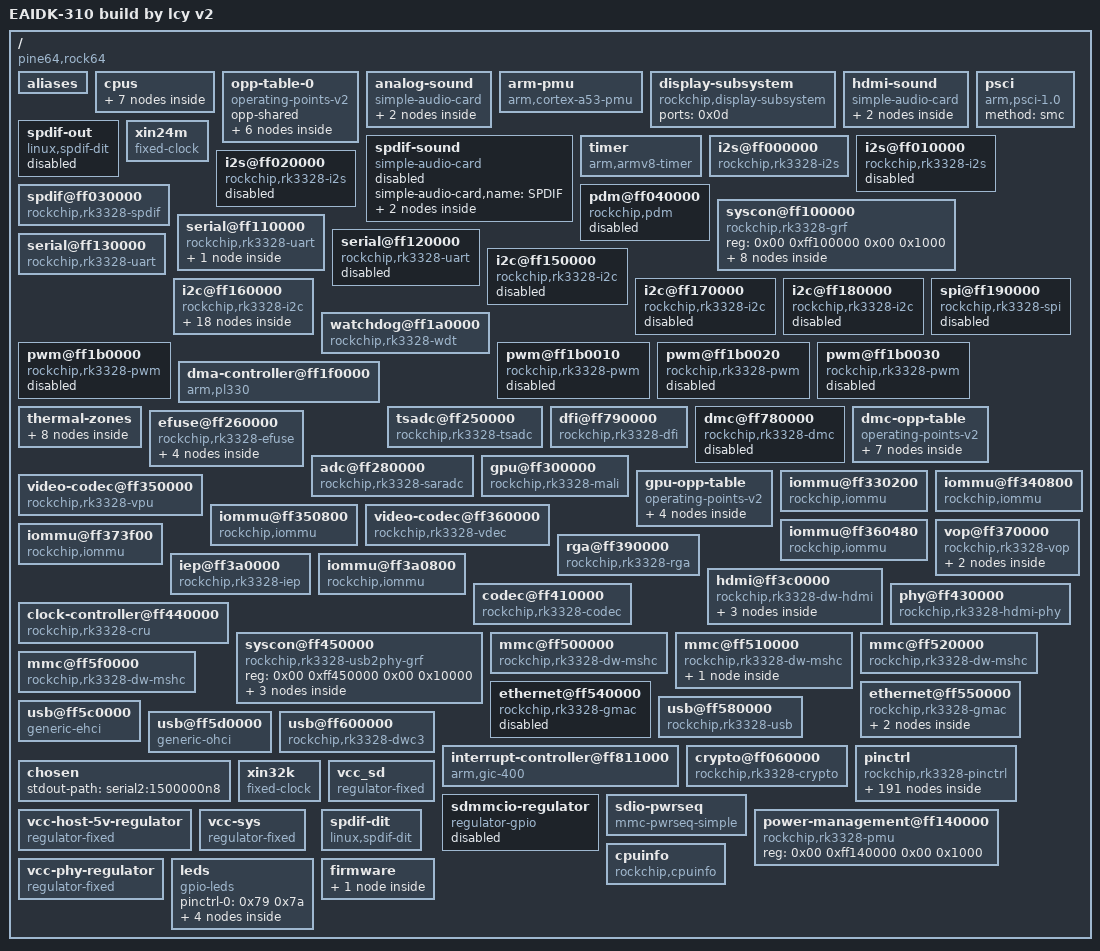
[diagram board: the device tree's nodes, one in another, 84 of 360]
/dts-v1/;

/ {
	compatible = "pine64,rock64\0rockchip,rk3328";
	interrupt-parent = <0x01>;
	#address-cells = <0x02>;
	#size-cells = <0x02>;
	model = "EAIDK-310 build by lcy v2";

	aliases {
		gpio0 = "/pinctrl/gpio@ff210000";
		gpio1 = "/pinctrl/gpio@ff220000";
		gpio2 = "/pinctrl/gpio@ff230000";
		gpio3 = "/pinctrl/gpio@ff240000";
		serial0 = "/serial@ff110000";
		serial1 = "/serial@ff120000";
		serial2 = "/serial@ff130000";
		i2c0 = "/i2c@ff150000";
		i2c1 = "/i2c@ff160000";
		i2c2 = "/i2c@ff170000";
		i2c3 = "/i2c@ff180000";
		mmc0 = "/mmc@ff500000";
		mmc1 = "/mmc@ff510000";
		mmc2 = "/mmc@ff520000";
		mmc3 = "/mmc@ff5f0000";
	};

	cpus {
		#address-cells = <0x02>;
		#size-cells = <0x00>;

		cpu@0 {
			device_type = "cpu";
			compatible = "arm,cortex-a53";
			reg = <0x00 0x00>;
			clocks = <0x02 0x06>;
			#cooling-cells = <0x02>;
			cpu-idle-states = <0x03>;
			dynamic-power-coefficient = <0x78>;
			enable-method = "psci";
			next-level-cache = <0x04>;
			operating-points-v2 = <0x05>;
			cpu-supply = <0x06>;
			phandle = <0x09>;
		};

		cpu@1 {
			device_type = "cpu";
			compatible = "arm,cortex-a53";
			reg = <0x00 0x01>;
			clocks = <0x02 0x06>;
			#cooling-cells = <0x02>;
			cpu-idle-states = <0x03>;
			dynamic-power-coefficient = <0x78>;
			enable-method = "psci";
			next-level-cache = <0x04>;
			operating-points-v2 = <0x05>;
			cpu-supply = <0x06>;
			phandle = <0x0a>;
		};

		cpu@2 {
			device_type = "cpu";
			compatible = "arm,cortex-a53";
			reg = <0x00 0x02>;
			clocks = <0x02 0x06>;
			#cooling-cells = <0x02>;
			cpu-idle-states = <0x03>;
			dynamic-power-coefficient = <0x78>;
			enable-method = "psci";
			next-level-cache = <0x04>;
			operating-points-v2 = <0x05>;
			cpu-supply = <0x06>;
			phandle = <0x0b>;
		};

		cpu@3 {
			device_type = "cpu";
			compatible = "arm,cortex-a53";
			reg = <0x00 0x03>;
			clocks = <0x02 0x06>;
			#cooling-cells = <0x02>;
			cpu-idle-states = <0x03>;
			dynamic-power-coefficient = <0x78>;
			enable-method = "psci";
			next-level-cache = <0x04>;
			operating-points-v2 = <0x05>;
			cpu-supply = <0x06>;
			phandle = <0x0c>;
		};

		idle-states {
			entry-method = "psci";

			cpu-sleep {
				compatible = "arm,idle-state";
				local-timer-stop;
				arm,psci-suspend-param = <0x10000>;
				entry-latency-us = <0x78>;
				exit-latency-us = <0xfa>;
				min-residency-us = <0x384>;
				phandle = <0x03>;
			};
		};

		l2-cache0 {
			compatible = "cache";
			cache-level = <0x02>;
			cache-unified;
			phandle = <0x04>;
		};
	};

	opp-table-0 {
		compatible = "operating-points-v2";
		opp-shared;
		phandle = <0x05>;

		opp-408000000 {
			opp-hz = <0x00 0x18519600>;
			opp-microvolt = <0xe7ef0>;
			clock-latency-ns = <0x9c40>;
			opp-suspend;
		};

		opp-600000000 {
			opp-hz = <0x00 0x23c34600>;
			opp-microvolt = <0xe7ef0>;
			clock-latency-ns = <0x9c40>;
		};

		opp-816000000 {
			opp-hz = <0x00 0x30a32c00>;
			opp-microvolt = <0xf4240>;
			clock-latency-ns = <0x9c40>;
		};

		opp-1008000000 {
			opp-hz = <0x00 0x3c14dc00>;
			opp-microvolt = <0x10c8e0>;
			clock-latency-ns = <0x9c40>;
		};

		opp-1200000000 {
			opp-hz = <0x00 0x47868c00>;
			opp-microvolt = <0x12b128>;
			clock-latency-ns = <0x9c40>;
		};

		opp-1296000000 {
			opp-hz = <0x00 0x4d3f6400>;
			opp-microvolt = <0x13d620>;
			clock-latency-ns = <0x9c40>;
		};
	};

	analog-sound {
		compatible = "simple-audio-card";
		simple-audio-card,format = "i2s";
		simple-audio-card,mclk-fs = <0x100>;
		simple-audio-card,name = "Analog";
		status = "okay";

		simple-audio-card,cpu {
			sound-dai = <0x07>;
		};

		simple-audio-card,codec {
			sound-dai = <0x08>;
		};
	};

	arm-pmu {
		compatible = "arm,cortex-a53-pmu";
		interrupts = <0x00 0x64 0x04 0x00 0x65 0x04 0x00 0x66 0x04 0x00 0x67 0x04>;
		interrupt-affinity = <0x09 0x0a 0x0b 0x0c>;
	};

	display-subsystem {
		compatible = "rockchip,display-subsystem";
		ports = <0x0d>;
	};

	hdmi-sound {
		compatible = "simple-audio-card";
		simple-audio-card,format = "i2s";
		simple-audio-card,mclk-fs = <0x80>;
		simple-audio-card,name = "HDMI";
		status = "okay";

		simple-audio-card,cpu {
			sound-dai = <0x0e>;
		};

		simple-audio-card,codec {
			sound-dai = <0x0f>;
		};
	};

	psci {
		compatible = "arm,psci-1.0\0arm,psci-0.2";
		method = "smc";
	};

	spdif-out {
		compatible = "linux,spdif-dit";
		#sound-dai-cells = <0x00>;
		status = "disabled";
	};

	spdif-sound {
		compatible = "simple-audio-card";
		simple-audio-card,name = "SPDIF";
		status = "disabled";

		simple-audio-card,cpu {
			sound-dai = <0x10>;
		};

		simple-audio-card,codec {
			sound-dai = <0x11>;
		};
	};

	timer {
		compatible = "arm,armv8-timer";
		interrupts = <0x01 0x0d 0xf08 0x01 0x0e 0xf08 0x01 0x0b 0xf08 0x01 0x0a 0xf08>;
	};

	xin24m {
		compatible = "fixed-clock";
		#clock-cells = <0x00>;
		clock-frequency = <0x16e3600>;
		clock-output-names = "xin24m";
		phandle = <0x51>;
	};

	i2s@ff000000 {
		compatible = "rockchip,rk3328-i2s\0rockchip,rk3066-i2s";
		reg = <0x00 0xff000000 0x00 0x1000>;
		interrupts = <0x00 0x1a 0x04>;
		clocks = <0x02 0x29 0x02 0x137>;
		clock-names = "i2s_clk\0i2s_hclk";
		dmas = <0x12 0x0b 0x12 0x0c>;
		dma-names = "tx\0rx";
		#sound-dai-cells = <0x00>;
		status = "okay";
		phandle = <0x0e>;
	};

	i2s@ff010000 {
		compatible = "rockchip,rk3328-i2s\0rockchip,rk3066-i2s";
		reg = <0x00 0xff010000 0x00 0x1000>;
		interrupts = <0x00 0x1b 0x04>;
		clocks = <0x02 0x2a 0x02 0x138>;
		clock-names = "i2s_clk\0i2s_hclk";
		dmas = <0x12 0x0e 0x12 0x0f>;
		dma-names = "tx\0rx";
		#sound-dai-cells = <0x00>;
		status = "disabled";
		phandle = <0x07>;
	};

	i2s@ff020000 {
		compatible = "rockchip,rk3328-i2s\0rockchip,rk3066-i2s";
		reg = <0x00 0xff020000 0x00 0x1000>;
		interrupts = <0x00 0x1c 0x04>;
		clocks = <0x02 0x2b 0x02 0x139>;
		clock-names = "i2s_clk\0i2s_hclk";
		dmas = <0x12 0x00 0x12 0x01>;
		dma-names = "tx\0rx";
		#sound-dai-cells = <0x00>;
		status = "disabled";
	};

	spdif@ff030000 {
		compatible = "rockchip,rk3328-spdif";
		reg = <0x00 0xff030000 0x00 0x1000>;
		interrupts = <0x00 0x1d 0x04>;
		clocks = <0x02 0x2e 0x02 0x13a>;
		clock-names = "mclk\0hclk";
		dmas = <0x12 0x0a>;
		dma-names = "tx";
		pinctrl-names = "default";
		pinctrl-0 = <0x13>;
		#sound-dai-cells = <0x00>;
		status = "okay";
		phandle = <0x10>;
	};

	pdm@ff040000 {
		compatible = "rockchip,pdm";
		reg = <0x00 0xff040000 0x00 0x1000>;
		clocks = <0x02 0x3d 0x02 0x152>;
		clock-names = "pdm_clk\0pdm_hclk";
		dmas = <0x12 0x10>;
		dma-names = "rx";
		pinctrl-names = "default\0sleep";
		pinctrl-0 = <0x14 0x15 0x16 0x17 0x18>;
		pinctrl-1 = <0x19 0x1a 0x1b 0x1c 0x1d>;
		status = "disabled";
	};

	syscon@ff100000 {
		compatible = "rockchip,rk3328-grf\0syscon\0simple-mfd";
		reg = <0x00 0xff100000 0x00 0x1000>;
		phandle = <0x40>;

		io-domains {
			compatible = "rockchip,rk3328-io-voltage-domain";
			status = "okay";
			vccio1-supply = <0x1e>;
			vccio2-supply = <0x1f>;
			vccio3-supply = <0x20>;
			vccio4-supply = <0x20>;
			vccio5-supply = <0x1e>;
			vccio6-supply = <0x1e>;
			pmuio-supply = <0x1e>;
		};

		gpio {
			compatible = "rockchip,rk3328-grf-gpio";
			gpio-controller;
			#gpio-cells = <0x02>;
			phandle = <0x50>;
		};

		power-controller {
			compatible = "rockchip,rk3328-power-controller";
			#power-domain-cells = <0x01>;
			#address-cells = <0x01>;
			#size-cells = <0x00>;
			phandle = <0x43>;

			power-domain@1 {
				reg = <0x01>;
				clocks = <0x02 0x87>;
			};

			power-domain@6 {
				reg = <0x06>;
				#power-domain-cells = <0x00>;
			};

			power-domain@5 {
				reg = <0x05>;
				clocks = <0x02 0x8b 0x02 0x142 0x02 0x41 0x02 0x42>;
				#power-domain-cells = <0x00>;
			};

			power-domain@8 {
				reg = <0x08>;
				clocks = <0x02 0x8f 0x02 0x146>;
				#power-domain-cells = <0x00>;
			};
		};

		reboot-mode {
			compatible = "syscon-reboot-mode";
			offset = <0x5c8>;
			mode-normal = <0x5242c300>;
			mode-recovery = <0x5242c303>;
			mode-bootloader = <0x5242c309>;
			mode-loader = <0x5242c301>;
		};
	};

	serial@ff110000 {
		compatible = "rockchip,rk3328-uart\0snps,dw-apb-uart";
		reg = <0x00 0xff110000 0x00 0x100>;
		interrupts = <0x00 0x37 0x04>;
		clocks = <0x02 0x26 0x02 0xd2>;
		clock-names = "baudclk\0apb_pclk";
		dmas = <0x12 0x02 0x12 0x03>;
		dma-names = "tx\0rx";
		pinctrl-names = "default";
		pinctrl-0 = <0x21 0x22 0x23>;
		reg-io-width = <0x04>;
		reg-shift = <0x02>;
		status = "okay";

		bluetooth {
			compatible = "brcm,bcm4345c5\0brcm,bcm4334b0-bt\0brcm,bcm4330-bt";
			clocks = <0x24 0x01>;
			clock-names = "lpo";
			host-wakeup-gpios = <0x25 0x1a 0x00>;
			shutdown-gpios = <0x25 0x15 0x00>;
			pinctrl-names = "default";
			max-speed = "\0=\t";
			pinctrl-0 = <0x26 0x27>;
			vbat-supply = <0x1e>;
			vddio-supply = <0x20>;
		};
	};

	serial@ff120000 {
		compatible = "rockchip,rk3328-uart\0snps,dw-apb-uart";
		reg = <0x00 0xff120000 0x00 0x100>;
		interrupts = <0x00 0x38 0x04>;
		clocks = <0x02 0x27 0x02 0xd3>;
		clock-names = "baudclk\0apb_pclk";
		dmas = <0x12 0x04 0x12 0x05>;
		dma-names = "tx\0rx";
		pinctrl-names = "default";
		pinctrl-0 = <0x28 0x29 0x2a>;
		reg-io-width = <0x04>;
		reg-shift = <0x02>;
		status = "disabled";
	};

	serial@ff130000 {
		compatible = "rockchip,rk3328-uart\0snps,dw-apb-uart";
		reg = <0x00 0xff130000 0x00 0x100>;
		interrupts = <0x00 0x39 0x04>;
		clocks = <0x02 0x28 0x02 0xd4>;
		clock-names = "baudclk\0apb_pclk";
		dmas = <0x12 0x06 0x12 0x07>;
		dma-names = "tx\0rx";
		pinctrl-names = "default";
		pinctrl-0 = <0x2b>;
		reg-io-width = <0x04>;
		reg-shift = <0x02>;
		status = "okay";
	};

	i2c@ff150000 {
		compatible = "rockchip,rk3328-i2c\0rockchip,rk3399-i2c";
		reg = <0x00 0xff150000 0x00 0x1000>;
		interrupts = <0x00 0x24 0x04>;
		#address-cells = <0x01>;
		#size-cells = <0x00>;
		clocks = <0x02 0x37 0x02 0xcd>;
		clock-names = "i2c\0pclk";
		pinctrl-names = "default";
		pinctrl-0 = <0x2c>;
		status = "disabled";
	};

	i2c@ff160000 {
		compatible = "rockchip,rk3328-i2c\0rockchip,rk3399-i2c";
		reg = <0x00 0xff160000 0x00 0x1000>;
		interrupts = <0x00 0x25 0x04>;
		#address-cells = <0x01>;
		#size-cells = <0x00>;
		clocks = <0x02 0x38 0x02 0xce>;
		clock-names = "i2c\0pclk";
		pinctrl-names = "default";
		pinctrl-0 = <0x2d>;
		status = "okay";

		pmic@18 {
			compatible = "rockchip,rk805";
			reg = <0x18>;
			interrupt-parent = <0x2e>;
			interrupts = <0x18 0x08>;
			#clock-cells = <0x01>;
			#gpio-cells = <0x02>;
			clock-output-names = "xin32k\0rk805-clkout2";
			gpio-controller;
			pinctrl-names = "default";
			pinctrl-0 = <0x2f>;
			rockchip,system-power-controller;
			wakeup-source;
			status = "okay";
			vcc1-supply = <0x30>;
			vcc2-supply = <0x30>;
			vcc3-supply = <0x30>;
			vcc4-supply = <0x30>;
			vcc5-supply = <0x1e>;
			vcc6-supply = <0x30>;
			phandle = <0x24>;

			rtc {
				status = "okay";
			};

			gpio {
				status = "okay";
			};

			regulators {
				compatible = "rk805-regulator";
				status = "okay";

				DCDC_REG1 {
					regulator-name = "vdd_logic";
					regulator-min-microvolt = <0xadf34>;
					regulator-max-microvolt = <0x162010>;
					regulator-ramp-delay = <0x30d4>;
					regulator-always-on;
					regulator-boot-on;
					phandle = <0x45>;

					regulator-state-mem {
						regulator-on-in-suspend;
						regulator-suspend-microvolt = <0xf4240>;
					};
				};

				DCDC_REG2 {
					regulator-name = "vdd_arm";
					regulator-min-microvolt = <0xadf34>;
					regulator-max-microvolt = <0x162010>;
					regulator-ramp-delay = <0x30d4>;
					regulator-always-on;
					regulator-boot-on;
					phandle = <0x06>;

					regulator-state-mem {
						regulator-on-in-suspend;
						regulator-suspend-microvolt = <0xe7ef0>;
					};
				};

				DCDC_REG3 {
					regulator-name = "vcc_ddr";
					regulator-always-on;
					regulator-boot-on;

					regulator-state-mem {
						regulator-on-in-suspend;
					};
				};

				DCDC_REG4 {
					regulator-name = "vcc_io";
					regulator-min-microvolt = <0x325aa0>;
					regulator-max-microvolt = <0x325aa0>;
					regulator-always-on;
					regulator-boot-on;
					phandle = <0x1e>;

					regulator-state-mem {
						regulator-on-in-suspend;
						regulator-suspend-microvolt = <0x325aa0>;
					};
				};

				LDO_REG1 {
					regulator-name = "vcc_18";
					regulator-min-microvolt = <0x1b7740>;
					regulator-max-microvolt = <0x1b7740>;
					regulator-always-on;
					regulator-boot-on;
					phandle = <0x20>;

					regulator-state-mem {
						regulator-on-in-suspend;
						regulator-suspend-microvolt = <0x1b7740>;
					};
				};

				LDO_REG2 {
					regulator-name = "vcc18_emmc";
					regulator-min-microvolt = <0x1b7740>;
					regulator-max-microvolt = <0x1b7740>;
					regulator-always-on;
					regulator-boot-on;
					phandle = <0x1f>;

					regulator-state-mem {
						regulator-on-in-suspend;
						regulator-suspend-microvolt = <0x1b7740>;
					};
				};

				LDO_REG3 {
					regulator-name = "vdd_10";
					regulator-min-microvolt = <0xf4240>;
					regulator-max-microvolt = <0xf4240>;
					regulator-always-on;
					regulator-boot-on;

					regulator-state-mem {
						regulator-on-in-suspend;
						regulator-suspend-microvolt = <0xf4240>;
					};
				};
			};
		};
	};

	i2c@ff170000 {
		compatible = "rockchip,rk3328-i2c\0rockchip,rk3399-i2c";
		reg = <0x00 0xff170000 0x00 0x1000>;
		interrupts = <0x00 0x26 0x04>;
		#address-cells = <0x01>;
		#size-cells = <0x00>;
		clocks = <0x02 0x39 0x02 0xcf>;
		clock-names = "i2c\0pclk";
		pinctrl-names = "default";
		pinctrl-0 = <0x31>;
		status = "disabled";
	};

	i2c@ff180000 {
		compatible = "rockchip,rk3328-i2c\0rockchip,rk3399-i2c";
		reg = <0x00 0xff180000 0x00 0x1000>;
		interrupts = <0x00 0x27 0x04>;
		#address-cells = <0x01>;
		#size-cells = <0x00>;
		clocks = <0x02 0x3a 0x02 0xd0>;
		clock-names = "i2c\0pclk";
		pinctrl-names = "default";
		pinctrl-0 = <0x32>;
		status = "disabled";
	};

	spi@ff190000 {
		compatible = "rockchip,rk3328-spi\0rockchip,rk3066-spi";
		reg = <0x00 0xff190000 0x00 0x1000>;
		interrupts = <0x00 0x31 0x04>;
		#address-cells = <0x01>;
		#size-cells = <0x00>;
		clocks = <0x02 0x20 0x02 0xd1>;
		clock-names = "spiclk\0apb_pclk";
		dmas = <0x12 0x08 0x12 0x09>;
		dma-names = "tx\0rx";
		pinctrl-names = "default";
		pinctrl-0 = <0x33 0x34 0x35 0x36>;
		status = "disabled";
	};

	watchdog@ff1a0000 {
		compatible = "rockchip,rk3328-wdt\0snps,dw-wdt";
		reg = <0x00 0xff1a0000 0x00 0x100>;
		interrupts = <0x00 0x28 0x04>;
		clocks = <0x02 0xec>;
	};

	pwm@ff1b0000 {
		compatible = "rockchip,rk3328-pwm";
		reg = <0x00 0xff1b0000 0x00 0x10>;
		clocks = <0x02 0x3c 0x02 0xd6>;
		clock-names = "pwm\0pclk";
		pinctrl-names = "default";
		pinctrl-0 = <0x37>;
		#pwm-cells = <0x03>;
		status = "disabled";
	};

	pwm@ff1b0010 {
		compatible = "rockchip,rk3328-pwm";
		reg = <0x00 0xff1b0010 0x00 0x10>;
		clocks = <0x02 0x3c 0x02 0xd6>;
		clock-names = "pwm\0pclk";
		pinctrl-names = "default";
		pinctrl-0 = <0x38>;
		#pwm-cells = <0x03>;
		status = "disabled";
	};

	pwm@ff1b0020 {
		compatible = "rockchip,rk3328-pwm";
		reg = <0x00 0xff1b0020 0x00 0x10>;
		clocks = <0x02 0x3c 0x02 0xd6>;
		clock-names = "pwm\0pclk";
		pinctrl-names = "default";
		pinctrl-0 = <0x39>;
		#pwm-cells = <0x03>;
		status = "disabled";
	};

	pwm@ff1b0030 {
		compatible = "rockchip,rk3328-pwm";
		reg = <0x00 0xff1b0030 0x00 0x10>;
		interrupts = <0x00 0x32 0x04>;
		clocks = <0x02 0x3c 0x02 0xd6>;
		clock-names = "pwm\0pclk";
		pinctrl-names = "default";
		pinctrl-0 = <0x3a>;
		#pwm-cells = <0x03>;
		status = "disabled";
	};

	dma-controller@ff1f0000 {
		compatible = "arm,pl330\0arm,primecell";
		reg = <0x00 0xff1f0000 0x00 0x4000>;
		interrupts = <0x00 0x00 0x04 0x00 0x01 0x04>;
		arm,pl330-periph-burst;
		clocks = <0x02 0x86>;
		clock-names = "apb_pclk";
		#dma-cells = <0x01>;
		phandle = <0x12>;
	};

	thermal-zones {

		soc-thermal {
			polling-delay-passive = <0x14>;
			polling-delay = <0x3e8>;
			sustainable-power = <0x3e8>;
			thermal-sensors = <0x3b 0x00>;

			trips {

				trip-point0 {
					temperature = <0x11170>;
					hysteresis = <0x7d0>;
					type = "passive";
				};

				trip-point1 {
					temperature = <0x14c08>;
					hysteresis = <0x7d0>;
					type = "passive";
					phandle = <0x3c>;
				};

				soc-crit {
					temperature = <0x17318>;
					hysteresis = <0x7d0>;
					type = "critical";
				};
			};

			cooling-maps {

				map0 {
					trip = <0x3c>;
					cooling-device = <0x09 0xffffffff 0xffffffff 0x0a 0xffffffff 0xffffffff 0x0b 0xffffffff 0xffffffff 0x0c 0xffffffff 0xffffffff>;
					contribution = <0x1000>;
				};

				map1 {
					trip = <0x3c>;
					cooling-device = <0x3d 0xffffffff 0xffffffff>;
					contribution = <0x1000>;
				};
			};
		};
	};

	tsadc@ff250000 {
		compatible = "rockchip,rk3328-tsadc";
		reg = <0x00 0xff250000 0x00 0x100>;
		interrupts = <0x00 0x3a 0x04>;
		assigned-clocks = <0x02 0x24>;
		assigned-clock-rates = <0xc350>;
		clocks = <0x02 0x24 0x02 0xd5>;
		clock-names = "tsadc\0apb_pclk";
		pinctrl-names = "init\0default\0sleep";
		pinctrl-0 = <0x3e>;
		pinctrl-1 = <0x3f>;
		pinctrl-2 = <0x3e>;
		resets = <0x02 0x42>;
		reset-names = "tsadc-apb";
		rockchip,grf = <0x40>;
		rockchip,hw-tshut-temp = <0x186a0>;
		#thermal-sensor-cells = <0x01>;
		status = "okay";
		rockchip,hw-tshut-mode = <0x00>;
		rockchip,hw-tshut-polarity = <0x00>;
		phandle = <0x3b>;
	};

	dfi@ff790000 {
		reg = <0x00 0xff790000 0x00 0x400>;
		compatible = "rockchip,rk3328-dfi";
		rockchip,grf = <0x40>;
		status = "okay";
		phandle = <0x41>;
	};

	dmc@ff780000 {
		reg = <0x00 0xff780000 0x00 0x400>;
		compatible = "rockchip,rk3328-dmc";
		devfreq-events = <0x41>;
		clocks = <0x02 0x40>;
		clock-names = "dmc_clk";
		operating-points-v2 = <0x42>;
		#cooling-cells = <0x02>;
		status = "disabled";
	};

	dmc-opp-table {
		compatible = "operating-points-v2";
		phandle = <0x42>;

		opp-600000000 {
			opp-hz = <0x00 0x23c34600>;
			opp-microvolt = <0xf4240 0xf4240 0x124f80>;
		};

		opp-666000000 {
			opp-hz = <0x00 0x27b25a80>;
			opp-microvolt = <0xfa3e8 0xfa3e8 0x124f80>;
		};

		opp-786000000 {
			opp-hz = <0x00 0x2ed96880>;
			opp-microvolt = <0x100590 0x100590 0x124f80>;
		};

		opp-800000000 {
			opp-hz = <0x00 0x2faf0800>;
			opp-microvolt = <0x100590 0x100590 0x124f80>;
			status = "disabled";
		};

		opp-850000000 {
			opp-hz = <0x00 0x32a9f880>;
			opp-microvolt = <0x100590 0x100590 0x124f80>;
			status = "disabled";
		};

		opp-933000000 {
			opp-hz = <0x00 0x379c7340>;
			opp-microvolt = <0x10c8e0 0x10c8e0 0x124f80>;
			status = "disabled";
		};

		opp-1066000000 {
			opp-hz = <0x00 0x3f89de80>;
			opp-microvolt = <0x118c30 0x118c30 0x124f80>;
			status = "disabled";
		};
	};

	efuse@ff260000 {
		compatible = "rockchip,rk3328-efuse";
		reg = <0x00 0xff260000 0x00 0x50>;
		#address-cells = <0x01>;
		#size-cells = <0x01>;
		clocks = <0x02 0x3e>;
		clock-names = "pclk_efuse";
		rockchip,efuse-size = <0x20>;

		id@7 {
			reg = <0x07 0x10>;
		};

		cpu-leakage@17 {
			reg = <0x17 0x01>;
		};

		logic-leakage@19 {
			reg = <0x19 0x01>;
		};

		cpu-version@1a {
			reg = <0x1a 0x01>;
			bits = <0x03 0x03>;
			phandle = <0x52>;
		};
	};

	adc@ff280000 {
		compatible = "rockchip,rk3328-saradc\0rockchip,rk3399-saradc";
		reg = <0x00 0xff280000 0x00 0x100>;
		interrupts = <0x00 0x50 0x04>;
		#io-channel-cells = <0x01>;
		clocks = <0x02 0x25 0x02 0xea>;
		clock-names = "saradc\0apb_pclk";
		resets = <0x02 0x56>;
		reset-names = "saradc-apb";
		status = "okay";
		vref-supply = <0x20>;
	};

	gpu@ff300000 {
		compatible = "rockchip,rk3328-mali\0arm,mali-450";
		reg = <0x00 0xff300000 0x00 0x30000>;
		interrupts = <0x00 0x5a 0x04 0x00 0x57 0x04 0x00 0x5d 0x04 0x00 0x58 0x04 0x00 0x59 0x04 0x00 0x5b 0x04 0x00 0x5c 0x04>;
		interrupt-names = "gp\0gpmmu\0pp\0pp0\0ppmmu0\0pp1\0ppmmu1";
		clocks = <0x02 0x87 0x02 0x87>;
		clock-names = "bus\0core";
		power-domains = <0x43 0x01>;
		resets = <0x02 0x66>;
		operating-points-v2 = <0x44>;
		#cooling-cells = <0x02>;
		status = "okay";
		mali-supply = <0x45>;
		phandle = <0x3d>;
	};

	gpu-opp-table {
		compatible = "operating-points-v2";
		phandle = <0x44>;

		opp-200000000 {
			opp-hz = <0x00 0xbebc200>;
			opp-microvolt = <0x100590 0xe7ef0 0x124f80>;
		};

		opp-300000000 {
			opp-hz = <0x00 0x11e1a300>;
			opp-microvolt = <0x100590 0xe7ef0 0x124f80>;
		};

		opp-400000000 {
			opp-hz = <0x00 0x17d78400>;
			opp-microvolt = <0x100590 0xe7ef0 0x124f80>;
		};

		opp-500000000 {
			opp-hz = <0x00 0x1dcd6500>;
			opp-microvolt = <0x118c30 0xe7ef0 0x124f80>;
		};
	};

	iommu@ff330200 {
		compatible = "rockchip,iommu";
		reg = <0x00 0xff330200 0x00 0x100>;
		interrupts = <0x00 0x60 0x04>;
		clocks = <0x02 0x93 0x02 0xdd>;
		clock-names = "aclk\0iface";
		#iommu-cells = <0x00>;
		status = "okay";
	};

	iommu@ff340800 {
		compatible = "rockchip,iommu";
		reg = <0x00 0xff340800 0x00 0x40>;
		interrupts = <0x00 0x62 0x04>;
		clocks = <0x02 0x8f 0x02 0x146>;
		clock-names = "aclk\0iface";
		#iommu-cells = <0x00>;
		status = "okay";
	};

	video-codec@ff350000 {
		compatible = "rockchip,rk3328-vpu";
		reg = <0x00 0xff350000 0x00 0x800>;
		interrupts = <0x00 0x09 0x04>;
		interrupt-names = "vdpu";
		clocks = <0x02 0x8f 0x02 0x146>;
		clock-names = "aclk\0hclk";
		iommus = <0x46>;
		power-domains = <0x43 0x08>;
		status = "okay";
		vcodec-supply = <0x45>;
	};

	iommu@ff350800 {
		compatible = "rockchip,iommu";
		reg = <0x00 0xff350800 0x00 0x40>;
		interrupts = <0x00 0x0b 0x04>;
		clocks = <0x02 0x8f 0x02 0x146>;
		clock-names = "aclk\0iface";
		#iommu-cells = <0x00>;
		power-domains = <0x43 0x08>;
		status = "okay";
		phandle = <0x46>;
	};

	video-codec@ff360000 {
		compatible = "rockchip,rk3328-vdec\0rockchip,rk3399-vdec";
		reg = <0x00 0xff360000 0x00 0x480>;
		interrupts = <0x00 0x07 0x04>;
		clocks = <0x02 0x8b 0x02 0x142 0x02 0x41 0x02 0x42>;
		clock-names = "axi\0ahb\0cabac\0core";
		assigned-clocks = <0x02 0x8b 0x02 0x41 0x02 0x42>;
		assigned-clock-rates = <0x17d78400 0x17d78400 0x11e1a300>;
		resets = <0x02 0xa6 0x02 0xa4 0x02 0xa8 0x02 0xa9 0x02 0xa5 0x02 0xa7>;
		reset-names = "video_h\0video_a\0video_core\0video_cabac\0niu_a\0niu_h";
		iommus = <0x47>;
		power-domains = <0x43 0x05>;
		status = "okay";
	};

	iommu@ff360480 {
		compatible = "rockchip,iommu";
		reg = <0x00 0xff360480 0x00 0x40 0x00 0xff3604c0 0x00 0x40>;
		interrupts = <0x00 0x4a 0x04>;
		clocks = <0x02 0x8b 0x02 0x142>;
		clock-names = "aclk\0iface";
		#iommu-cells = <0x00>;
		power-domains = <0x43 0x05>;
		status = "okay";
		phandle = <0x47>;
	};

	vop@ff370000 {
		compatible = "rockchip,rk3328-vop";
		reg = <0x00 0xff370000 0x00 0x3efc>;
		interrupts = <0x00 0x20 0x04>;
		clocks = <0x02 0x91 0x02 0x78 0x02 0x13b>;
		clock-names = "aclk_vop\0dclk_vop\0hclk_vop";
		resets = <0x02 0x85 0x02 0x86 0x02 0x87>;
		reset-names = "axi\0ahb\0dclk";
		iommus = <0x48>;
		status = "okay";

		port {
			#address-cells = <0x01>;
			#size-cells = <0x00>;
			phandle = <0x0d>;

			endpoint@0 {
				reg = <0x00>;
				remote-endpoint = <0x49>;
				phandle = <0x4f>;
			};
		};
	};

	iommu@ff373f00 {
		compatible = "rockchip,iommu";
		reg = <0x00 0xff373f00 0x00 0x100>;
		interrupts = <0x00 0x20 0x04>;
		clocks = <0x02 0x91 0x02 0x13b>;
		clock-names = "aclk\0iface";
		#iommu-cells = <0x00>;
		status = "okay";
		phandle = <0x48>;
	};

	rga@ff390000 {
		compatible = "rockchip,rk3328-rga\0rockchip,rk3399-rga";
		reg = <0x00 0xff390000 0x00 0x1000>;
		interrupts = <0x00 0x21 0x04>;
		clocks = <0x02 0x9a 0x02 0x154 0x02 0x45>;
		clock-names = "aclk\0hclk\0sclk";
		resets = <0x02 0x88 0x02 0x8a 0x02 0x8b>;
		reset-names = "core\0axi\0ahb";
		status = "okay";
	};

	iep@ff3a0000 {
		compatible = "rockchip,rk3328-iep\0rockchip,rk3228-iep";
		reg = <0x00 0xff3a0000 0x00 0x800>;
		interrupts = <0x00 0x1f 0x04>;
		interrupt-names = "iep";
		clocks = <0x02 0x9b 0x02 0x153>;
		clock-names = "axi\0ahb";
		power-domains = <0x43 0x05>;
		iommus = <0x4a>;
		status = "okay";
	};

	iommu@ff3a0800 {
		compatible = "rockchip,iommu";
		reg = <0x00 0xff3a0800 0x00 0x40>;
		interrupts = <0x00 0x1f 0x04>;
		interrupt-names = "iep_mmu";
		clocks = <0x02 0x9b 0x02 0x153>;
		clock-names = "aclk\0iface";
		power-domains = <0x43 0x05>;
		#iommu-cells = <0x00>;
		phandle = <0x4a>;
	};

	hdmi@ff3c0000 {
		compatible = "rockchip,rk3328-dw-hdmi";
		reg = <0x00 0xff3c0000 0x00 0x20000>;
		reg-io-width = <0x04>;
		interrupts = <0x00 0x23 0x04 0x00 0x47 0x04>;
		clocks = <0x02 0xe7 0x02 0x46 0x02 0x1e>;
		clock-names = "iahb\0isfr\0cec";
		phys = <0x4b>;
		phy-names = "hdmi";
		pinctrl-names = "default";
		pinctrl-0 = <0x4c 0x4d 0x4e>;
		rockchip,grf = <0x40>;
		#sound-dai-cells = <0x00>;
		status = "okay";
		phandle = <0x0f>;

		ports {

			port {

				endpoint {
					remote-endpoint = <0x4f>;
					phandle = <0x49>;
				};
			};
		};
	};

	codec@ff410000 {
		compatible = "rockchip,rk3328-codec";
		reg = <0x00 0xff410000 0x00 0x1000>;
		clocks = <0x02 0xeb 0x02 0x2a>;
		clock-names = "pclk\0mclk";
		rockchip,grf = <0x40>;
		#sound-dai-cells = <0x00>;
		status = "okay";
		mute-gpios = <0x50 0x00 0x01>;
		phandle = <0x08>;
	};

	phy@ff430000 {
		compatible = "rockchip,rk3328-hdmi-phy";
		reg = <0x00 0xff430000 0x00 0x10000>;
		interrupts = <0x00 0x53 0x04>;
		clocks = <0x02 0xe4 0x51 0x02 0x79>;
		clock-names = "sysclk\0refoclk\0refpclk";
		clock-output-names = "hdmi_phy";
		#clock-cells = <0x00>;
		nvmem-cells = <0x52>;
		nvmem-cell-names = "cpu-version";
		#phy-cells = <0x00>;
		status = "okay";
		phandle = <0x4b>;
	};

	clock-controller@ff440000 {
		compatible = "rockchip,rk3328-cru\0rockchip,cru\0syscon";
		reg = <0x00 0xff440000 0x00 0x1000>;
		rockchip,grf = <0x40>;
		#clock-cells = <0x01>;
		#reset-cells = <0x01>;
		assigned-clocks = <0x02 0x78 0x02 0x3d 0x02 0x1e 0x02 0x26 0x02 0x27 0x02 0x28 0x02 0x88 0x02 0x89 0x02 0x8e 0x02 0x85 0x02 0x83 0x02 0x8a 0x02 0x8c 0x02 0x8d 0x02 0x41 0x02 0x42 0x02 0x44 0x02 0x43 0x02 0x22 0x02 0x5c 0x02 0x35 0x02 0x06 0x02 0x04 0x02 0x03 0x02 0x88 0x02 0x148 0x02 0xd8 0x02 0x89 0x02 0x134 0x02 0xe6 0x02 0x87 0x02 0x1e>;
		assigned-clock-parents = <0x02 0x7a 0x02 0x01 0x02 0x04 0x51 0x51 0x51>;
		assigned-clock-rates = <0x00 0x3a98000 0x00 0x16e3600 0x16e3600 0x16e3600 0xe4e1c0 0xe4e1c0 0x5f5e100 0x5f5e100 0x5f5e100 0x5f5e100 0x2faf080 0x5f5e100 0x5f5e100 0x5f5e100 0x2faf080 0x2faf080 0x2faf080 0x2faf080 0x16e3600 0x23c34600 0x1d4c0000 0x47868c00 0x8f0d180 0x47868c0 0x47868c0 0x8f0d180 0x47868c0 0x47868c0 0x1dcd6500 0x8000>;
		phandle = <0x02>;
	};

	syscon@ff450000 {
		compatible = "rockchip,rk3328-usb2phy-grf\0syscon\0simple-mfd";
		reg = <0x00 0xff450000 0x00 0x10000>;
		#address-cells = <0x01>;
		#size-cells = <0x01>;

		usb2phy@100 {
			compatible = "rockchip,rk3328-usb2phy";
			reg = <0x100 0x10>;
			clocks = <0x51>;
			clock-names = "phyclk";
			clock-output-names = "usb480m_phy";
			#clock-cells = <0x00>;
			assigned-clocks = <0x02 0x7b>;
			assigned-clock-parents = <0x53>;
			status = "okay";
			phandle = <0x53>;

			otg-port {
				#phy-cells = <0x00>;
				interrupts = <0x00 0x3b 0x04 0x00 0x3c 0x04 0x00 0x3d 0x04>;
				interrupt-names = "otg-bvalid\0otg-id\0linestate";
				status = "okay";
				phandle = <0x68>;
			};

			host-port {
				#phy-cells = <0x00>;
				interrupts = <0x00 0x3e 0x04>;
				interrupt-names = "linestate";
				status = "okay";
				phandle = <0x69>;
			};
		};
	};

	mmc@ff500000 {
		compatible = "rockchip,rk3328-dw-mshc\0rockchip,rk3288-dw-mshc";
		reg = <0x00 0xff500000 0x00 0x4000>;
		interrupts = <0x00 0x0c 0x04>;
		clocks = <0x02 0x13d 0x02 0x21 0x02 0x4a 0x02 0x4e>;
		clock-names = "biu\0ciu\0ciu-drive\0ciu-sample";
		resets = <0x02 0x6d>;
		reset-names = "reset";
		fifo-depth = <0x100>;
		max-frequency = <0x8f0d180>;
		status = "okay";
		bus-width = <0x04>;
		cap-mmc-highspeed;
		cap-sd-highspeed;
		disable-wp;
		sd-uhs-sdr50;
		sd-uhs-sdr104;
		pinctrl-names = "default";
		pinctrl-0 = <0x54 0x55 0x56 0x57>;
		vmmc-supply = <0x58>;
	};

	mmc@ff510000 {
		compatible = "rockchip,rk3328-dw-mshc\0rockchip,rk3288-dw-mshc";
		reg = <0x00 0xff510000 0x00 0x4000>;
		interrupts = <0x00 0x0d 0x04>;
		clocks = <0x02 0x13e 0x02 0x22 0x02 0x4b 0x02 0x4f>;
		clock-names = "biu\0ciu\0ciu-drive\0ciu-sample";
		resets = <0x02 0x6e>;
		reset-names = "reset";
		fifo-depth = <0x100>;
		max-frequency = <0x4a817c80>;
		status = "okay";
		#address-cells = <0x01>;
		#size-cells = <0x00>;
		bus-width = <0x04>;
		cap-sd-highspeed;
		cap-sdio-irq;
		disable-wp;
		num-slots = <0x01>;
		mmc-pwrseq = <0x59>;
		non-removable;
		pinctrl-names = "default";
		pinctrl-0 = <0x5a 0x5b 0x5c 0x5d>;
		sd-uhs-sdr104;

		wifi@1 {
			reg = <0x01>;
			compatible = "brcm,bcm4329-fmac";
			interrupt-parent = <0x25>;
			interrupts = <0x13 0x04>;
			interrupt-names = "host-wake";
		};
	};

	mmc@ff520000 {
		compatible = "rockchip,rk3328-dw-mshc\0rockchip,rk3288-dw-mshc";
		reg = <0x00 0xff520000 0x00 0x4000>;
		interrupts = <0x00 0x0e 0x04>;
		clocks = <0x02 0x13f 0x02 0x23 0x02 0x4c 0x02 0x50>;
		clock-names = "biu\0ciu\0ciu-drive\0ciu-sample";
		resets = <0x02 0x6f>;
		reset-names = "reset";
		fifo-depth = <0x100>;
		max-frequency = <0x8f0d180>;
		status = "okay";
		bus-width = <0x08>;
		cap-mmc-highspeed;
		mmc-hs200-1_8v;
		non-removable;
		pinctrl-names = "default";
		pinctrl-0 = <0x5e 0x5f 0x60>;
		vmmc-supply = <0x1e>;
		vqmmc-supply = <0x1f>;
	};

	mmc@ff5f0000 {
		compatible = "rockchip,rk3328-dw-mshc\0rockchip,rk3288-dw-mshc";
		reg = <0x00 0xff5f0000 0x00 0x4000>;
		interrupts = <0x00 0x04 0x04>;
		clocks = <0x02 0x140 0x02 0x1f 0x02 0x4d 0x02 0x51>;
		clock-names = "biu\0ciu\0ciu-drive\0ciu-sample";
		fifo-depth = <0x100>;
		max-frequency = <0x8f0d180>;
		resets = <0x02 0x68>;
		reset-names = "reset";
		status = "okay";
		bus-width = <0x01>;
		cap-mmc-highspeed;
		cap-sd-highspeed;
		cap-sdio-irq;
		disable-wp;
		non-removable;
		keep-power-in-suspend;
		num-slots = <0x01>;
		pinctrl-names = "default";
		pinctrl-0 = <0x61 0x62 0x63>;
		sd-uhs-sdr104;
		supports-sdio;
	};

	ethernet@ff540000 {
		compatible = "rockchip,rk3328-gmac";
		reg = <0x00 0xff540000 0x00 0x10000>;
		interrupts = <0x00 0x18 0x04>;
		interrupt-names = "macirq";
		clocks = <0x02 0x64 0x02 0x57 0x02 0x58 0x02 0x5a 0x02 0x59 0x02 0x96 0x02 0xdf>;
		clock-names = "stmmaceth\0mac_clk_rx\0mac_clk_tx\0clk_mac_ref\0clk_mac_refout\0aclk_mac\0pclk_mac";
		resets = <0x02 0x63>;
		reset-names = "stmmaceth";
		rockchip,grf = <0x40>;
		tx-fifo-depth = <0x800>;
		rx-fifo-depth = <0x1000>;
		snps,txpbl = <0x04>;
		status = "disabled";
	};

	ethernet@ff550000 {
		compatible = "rockchip,rk3328-gmac";
		reg = <0x00 0xff550000 0x00 0x10000>;
		rockchip,grf = <0x40>;
		interrupts = <0x00 0x15 0x04>;
		interrupt-names = "macirq";
		clocks = <0x02 0x54 0x02 0x53 0x02 0x53 0x02 0x55 0x02 0x95 0x02 0xde 0x02 0x56>;
		clock-names = "stmmaceth\0mac_clk_rx\0mac_clk_tx\0clk_mac_ref\0aclk_mac\0pclk_mac\0clk_macphy";
		resets = <0x02 0x62>;
		reset-names = "stmmaceth";
		phy-mode = "rmii";
		phy-handle = <0x64>;
		tx-fifo-depth = <0x800>;
		rx-fifo-depth = <0x1000>;
		snps,txpbl = <0x04>;
		clock_in_out = "output";
		status = "okay";
		phy-supply = <0x65>;
		assigned-clock-rate = <0x2faf080>;
		assigned-clocks = <0x02 0x65>;
		assigned-clock-parents = <0x02 0x54>;

		mdio {
			compatible = "snps,dwmac-mdio";
			#address-cells = <0x01>;
			#size-cells = <0x00>;

			ethernet-phy@0 {
				compatible = "ethernet-phy-id1234.d400\0ethernet-phy-ieee802.3-c22";
				reg = <0x00>;
				clocks = <0x02 0x56>;
				resets = <0x02 0x64>;
				pinctrl-names = "default";
				pinctrl-0 = <0x66 0x67>;
				phy-is-integrated;
				phandle = <0x64>;
			};
		};
	};

	usb@ff580000 {
		compatible = "rockchip,rk3328-usb\0rockchip,rk3066-usb\0snps,dwc2";
		reg = <0x00 0xff580000 0x00 0x40000>;
		interrupts = <0x00 0x17 0x04>;
		clocks = <0x02 0x14d>;
		clock-names = "otg";
		dr_mode = "host";
		g-np-tx-fifo-size = <0x10>;
		g-rx-fifo-size = <0x118>;
		g-tx-fifo-size = <0x100 0x80 0x80 0x40 0x20 0x10>;
		phys = <0x68>;
		phy-names = "usb2-phy";
		status = "okay";
	};

	usb@ff5c0000 {
		compatible = "generic-ehci";
		reg = <0x00 0xff5c0000 0x00 0x10000>;
		interrupts = <0x00 0x10 0x04>;
		clocks = <0x02 0x14e 0x53>;
		phys = <0x69>;
		phy-names = "usb";
		status = "okay";
	};

	usb@ff5d0000 {
		compatible = "generic-ohci";
		reg = <0x00 0xff5d0000 0x00 0x10000>;
		interrupts = <0x00 0x11 0x04>;
		clocks = <0x02 0x14e 0x53>;
		phys = <0x69>;
		phy-names = "usb";
		status = "okay";
	};

	usb@ff600000 {
		compatible = "rockchip,rk3328-dwc3\0snps,dwc3";
		reg = <0x00 0xff600000 0x00 0x100000>;
		interrupts = <0x00 0x43 0x04>;
		clocks = <0x02 0x60 0x02 0x61 0x02 0x84>;
		clock-names = "ref_clk\0suspend_clk\0bus_clk";
		resets = <0x02 0x78>;
		reset-names = "usb3-otg";
		dr_mode = "host";
		phy_type = "utmi_wide";
		snps,dis-del-phy-power-chg-quirk;
		snps,dis_enblslpm_quirk;
		snps,dis-tx-ipgap-linecheck-quirk;
		snps,xhci-trb-ent-quirk;
		snps,dis-u2-freeclk-exists-quirk;
		snps,dis_u2_susphy_quirk;
		snps,dis_u3_susphy_quirk;
		status = "okay";
	};

	interrupt-controller@ff811000 {
		compatible = "arm,gic-400";
		#interrupt-cells = <0x03>;
		#address-cells = <0x00>;
		interrupt-controller;
		reg = <0x00 0xff811000 0x00 0x1000 0x00 0xff812000 0x00 0x2000 0x00 0xff814000 0x00 0x2000 0x00 0xff816000 0x00 0x2000>;
		interrupts = <0x01 0x09 0xf04>;
		phandle = <0x01>;
	};

	crypto@ff060000 {
		compatible = "rockchip,rk3328-crypto";
		reg = <0x00 0xff060000 0x00 0x4000>;
		interrupts = <0x00 0x1e 0x04>;
		clocks = <0x02 0x150 0x02 0x151 0x02 0x3b>;
		clock-names = "hclk_master\0hclk_slave\0sclk";
		resets = <0x02 0x44>;
		reset-names = "crypto-rst";
	};

	pinctrl {
		compatible = "rockchip,rk3328-pinctrl";
		rockchip,grf = <0x40>;
		#address-cells = <0x02>;
		#size-cells = <0x02>;
		ranges;
		pinctrl-0 = <0x5d>;

		gpio@ff210000 {
			compatible = "rockchip,gpio-bank";
			reg = <0x00 0xff210000 0x00 0x100>;
			interrupts = <0x00 0x33 0x04>;
			clocks = <0x02 0xc8>;
			gpio-controller;
			#gpio-cells = <0x02>;
			interrupt-controller;
			#interrupt-cells = <0x02>;
			phandle = <0x75>;
		};

		gpio@ff220000 {
			compatible = "rockchip,gpio-bank";
			reg = <0x00 0xff220000 0x00 0x100>;
			interrupts = <0x00 0x34 0x04>;
			clocks = <0x02 0xc9>;
			gpio-controller;
			#gpio-cells = <0x02>;
			interrupt-controller;
			#interrupt-cells = <0x02>;
			phandle = <0x25>;
		};

		gpio@ff230000 {
			compatible = "rockchip,gpio-bank";
			reg = <0x00 0xff230000 0x00 0x100>;
			interrupts = <0x00 0x35 0x04>;
			clocks = <0x02 0xca>;
			gpio-controller;
			#gpio-cells = <0x02>;
			interrupt-controller;
			#interrupt-cells = <0x02>;
			phandle = <0x2e>;
		};

		gpio@ff240000 {
			compatible = "rockchip,gpio-bank";
			reg = <0x00 0xff240000 0x00 0x100>;
			interrupts = <0x00 0x36 0x04>;
			clocks = <0x02 0xcb>;
			gpio-controller;
			#gpio-cells = <0x02>;
			interrupt-controller;
			#interrupt-cells = <0x02>;
		};

		pcfg-pull-up {
			bias-pull-up;
			phandle = <0x6c>;
		};

		pcfg-pull-down {
			bias-pull-down;
			phandle = <0x74>;
		};

		pcfg-pull-none {
			bias-disable;
			phandle = <0x6a>;
		};

		pcfg-pull-none-2ma {
			bias-disable;
			drive-strength = <0x02>;
			phandle = <0x73>;
		};

		pcfg-pull-up-2ma {
			bias-pull-up;
			drive-strength = <0x02>;
		};

		pcfg-pull-up-4ma {
			bias-pull-up;
			drive-strength = <0x04>;
			phandle = <0x6d>;
		};

		pcfg-pull-none-4ma {
			bias-disable;
			drive-strength = <0x04>;
			phandle = <0x70>;
		};

		pcfg-pull-down-4ma {
			bias-pull-down;
			drive-strength = <0x04>;
		};

		pcfg-pull-none-8ma {
			bias-disable;
			drive-strength = <0x08>;
			phandle = <0x6e>;
		};

		pcfg-pull-up-8ma {
			bias-pull-up;
			drive-strength = <0x08>;
			phandle = <0x6f>;
		};

		pcfg-pull-none-12ma {
			bias-disable;
			drive-strength = <0x0c>;
			phandle = <0x71>;
		};

		pcfg-pull-up-12ma {
			bias-pull-up;
			drive-strength = <0x0c>;
			phandle = <0x72>;
		};

		pcfg-output-high {
			output-high;
		};

		pcfg-output-low {
			output-low;
		};

		pcfg-input-high {
			bias-pull-up;
			input-enable;
			phandle = <0x6b>;
		};

		pcfg-input {
			input-enable;
		};

		i2c0 {

			i2c0-xfer {
				rockchip,pins = <0x02 0x18 0x01 0x6a 0x02 0x19 0x01 0x6a>;
				phandle = <0x2c>;
			};
		};

		i2c1 {

			i2c1-xfer {
				rockchip,pins = <0x02 0x04 0x02 0x6a 0x02 0x05 0x02 0x6a>;
				phandle = <0x2d>;
			};
		};

		i2c2 {

			i2c2-xfer {
				rockchip,pins = <0x02 0x0d 0x01 0x6a 0x02 0x0e 0x01 0x6a>;
				phandle = <0x31>;
			};
		};

		i2c3 {

			i2c3-xfer {
				rockchip,pins = <0x00 0x05 0x02 0x6a 0x00 0x06 0x02 0x6a>;
				phandle = <0x32>;
			};

			i2c3-pins {
				rockchip,pins = <0x00 0x05 0x00 0x6a 0x00 0x06 0x00 0x6a>;
			};
		};

		hdmi_i2c {

			hdmii2c-xfer {
				rockchip,pins = <0x00 0x05 0x01 0x6a 0x00 0x06 0x01 0x6a>;
				phandle = <0x4d>;
			};
		};

		pdm-0 {

			pdmm0-clk {
				rockchip,pins = <0x02 0x12 0x02 0x6a>;
				phandle = <0x14>;
			};

			pdmm0-fsync {
				rockchip,pins = <0x02 0x17 0x02 0x6a>;
			};

			pdmm0-sdi0 {
				rockchip,pins = <0x02 0x13 0x02 0x6a>;
				phandle = <0x15>;
			};

			pdmm0-sdi1 {
				rockchip,pins = <0x02 0x14 0x02 0x6a>;
				phandle = <0x16>;
			};

			pdmm0-sdi2 {
				rockchip,pins = <0x02 0x15 0x02 0x6a>;
				phandle = <0x17>;
			};

			pdmm0-sdi3 {
				rockchip,pins = <0x02 0x16 0x02 0x6a>;
				phandle = <0x18>;
			};

			pdmm0-clk-sleep {
				rockchip,pins = <0x02 0x12 0x00 0x6b>;
				phandle = <0x19>;
			};

			pdmm0-sdi0-sleep {
				rockchip,pins = <0x02 0x13 0x00 0x6b>;
				phandle = <0x1a>;
			};

			pdmm0-sdi1-sleep {
				rockchip,pins = <0x02 0x14 0x00 0x6b>;
				phandle = <0x1b>;
			};

			pdmm0-sdi2-sleep {
				rockchip,pins = <0x02 0x15 0x00 0x6b>;
				phandle = <0x1c>;
			};

			pdmm0-sdi3-sleep {
				rockchip,pins = <0x02 0x16 0x00 0x6b>;
				phandle = <0x1d>;
			};

			pdmm0-fsync-sleep {
				rockchip,pins = <0x02 0x17 0x00 0x6b>;
			};
		};

		tsadc {

			otp-pin {
				rockchip,pins = <0x02 0x0d 0x00 0x6a>;
				phandle = <0x3e>;
			};

			otp-out {
				rockchip,pins = <0x02 0x0d 0x01 0x6a>;
				phandle = <0x3f>;
			};
		};

		uart0 {

			uart0-xfer {
				rockchip,pins = <0x01 0x09 0x01 0x6a 0x01 0x08 0x01 0x6c>;
				phandle = <0x21>;
			};

			uart0-cts {
				rockchip,pins = <0x01 0x0b 0x01 0x6a>;
				phandle = <0x22>;
			};

			uart0-rts {
				rockchip,pins = <0x01 0x0a 0x01 0x6a>;
				phandle = <0x23>;
			};

			uart0-rts-pin {
				rockchip,pins = <0x01 0x0a 0x00 0x6a>;
			};
		};

		uart1 {

			uart1-xfer {
				rockchip,pins = <0x03 0x04 0x04 0x6a 0x03 0x06 0x04 0x6c>;
				phandle = <0x28>;
			};

			uart1-cts {
				rockchip,pins = <0x03 0x07 0x04 0x6a>;
				phandle = <0x29>;
			};

			uart1-rts {
				rockchip,pins = <0x03 0x05 0x04 0x6a>;
				phandle = <0x2a>;
			};

			uart1-rts-pin {
				rockchip,pins = <0x03 0x05 0x00 0x6a>;
			};
		};

		uart2-0 {

			uart2m0-xfer {
				rockchip,pins = <0x01 0x00 0x02 0x6a 0x01 0x01 0x02 0x6c>;
			};
		};

		uart2-1 {

			uart2m1-xfer {
				rockchip,pins = <0x02 0x00 0x01 0x6a 0x02 0x01 0x01 0x6c>;
				phandle = <0x2b>;
			};
		};

		spi0-0 {

			spi0m0-clk {
				rockchip,pins = <0x02 0x08 0x01 0x6c>;
			};

			spi0m0-cs0 {
				rockchip,pins = <0x02 0x0b 0x01 0x6c>;
			};

			spi0m0-tx {
				rockchip,pins = <0x02 0x09 0x01 0x6c>;
			};

			spi0m0-rx {
				rockchip,pins = <0x02 0x0a 0x01 0x6c>;
			};

			spi0m0-cs1 {
				rockchip,pins = <0x02 0x0c 0x01 0x6c>;
			};
		};

		spi0-1 {

			spi0m1-clk {
				rockchip,pins = <0x03 0x17 0x02 0x6c>;
			};

			spi0m1-cs0 {
				rockchip,pins = <0x03 0x1a 0x02 0x6c>;
			};

			spi0m1-tx {
				rockchip,pins = <0x03 0x19 0x02 0x6c>;
			};

			spi0m1-rx {
				rockchip,pins = <0x03 0x18 0x02 0x6c>;
			};

			spi0m1-cs1 {
				rockchip,pins = <0x03 0x1b 0x02 0x6c>;
			};
		};

		spi0-2 {

			spi0m2-clk {
				rockchip,pins = <0x03 0x00 0x04 0x6c>;
				phandle = <0x33>;
			};

			spi0m2-cs0 {
				rockchip,pins = <0x03 0x08 0x03 0x6c>;
				phandle = <0x36>;
			};

			spi0m2-tx {
				rockchip,pins = <0x03 0x01 0x04 0x6c>;
				phandle = <0x34>;
			};

			spi0m2-rx {
				rockchip,pins = <0x03 0x02 0x04 0x6c>;
				phandle = <0x35>;
			};
		};

		i2s1 {

			i2s1-mclk {
				rockchip,pins = <0x02 0x0f 0x01 0x6a>;
			};

			i2s1-sclk {
				rockchip,pins = <0x02 0x12 0x01 0x6a>;
			};

			i2s1-lrckrx {
				rockchip,pins = <0x02 0x10 0x01 0x6a>;
			};

			i2s1-lrcktx {
				rockchip,pins = <0x02 0x11 0x01 0x6a>;
			};

			i2s1-sdi {
				rockchip,pins = <0x02 0x13 0x01 0x6a>;
			};

			i2s1-sdo {
				rockchip,pins = <0x02 0x17 0x01 0x6a>;
			};

			i2s1-sdio1 {
				rockchip,pins = <0x02 0x14 0x01 0x6a>;
			};

			i2s1-sdio2 {
				rockchip,pins = <0x02 0x15 0x01 0x6c>;
			};

			i2s1-sdio3 {
				rockchip,pins = <0x02 0x16 0x01 0x6c>;
			};

			i2s1-sleep {
				rockchip,pins = <0x02 0x0f 0x00 0x6b 0x02 0x10 0x00 0x6b 0x02 0x11 0x00 0x6b 0x02 0x12 0x00 0x6b 0x02 0x13 0x00 0x6b 0x02 0x14 0x00 0x6b 0x02 0x15 0x00 0x6b 0x02 0x16 0x00 0x6b 0x02 0x17 0x00 0x6b>;
			};
		};

		i2s2-0 {

			i2s2m0-mclk {
				rockchip,pins = <0x01 0x15 0x01 0x6a>;
			};

			i2s2m0-sclk {
				rockchip,pins = <0x01 0x16 0x01 0x6a>;
			};

			i2s2m0-lrckrx {
				rockchip,pins = <0x01 0x1a 0x01 0x6a>;
			};

			i2s2m0-lrcktx {
				rockchip,pins = <0x01 0x17 0x01 0x6a>;
			};

			i2s2m0-sdi {
				rockchip,pins = <0x01 0x18 0x01 0x6a>;
			};

			i2s2m0-sdo {
				rockchip,pins = <0x01 0x19 0x01 0x6a>;
			};

			i2s2m0-sleep {
				rockchip,pins = <0x01 0x15 0x00 0x6b 0x01 0x16 0x00 0x6b 0x01 0x1a 0x00 0x6b 0x01 0x17 0x00 0x6b 0x01 0x18 0x00 0x6b 0x01 0x19 0x00 0x6b>;
			};
		};

		i2s2-1 {

			i2s2m1-mclk {
				rockchip,pins = <0x01 0x15 0x01 0x6a>;
			};

			i2s2m1-sclk {
				rockchip,pins = <0x03 0x00 0x06 0x6a>;
			};

			i2sm1-lrckrx {
				rockchip,pins = <0x03 0x08 0x06 0x6a>;
			};

			i2s2m1-lrcktx {
				rockchip,pins = <0x03 0x08 0x04 0x6a>;
			};

			i2s2m1-sdi {
				rockchip,pins = <0x03 0x02 0x06 0x6a>;
			};

			i2s2m1-sdo {
				rockchip,pins = <0x03 0x01 0x06 0x6a>;
			};

			i2s2m1-sleep {
				rockchip,pins = <0x01 0x15 0x00 0x6b 0x03 0x00 0x00 0x6b 0x03 0x08 0x00 0x6b 0x03 0x02 0x00 0x6b 0x03 0x01 0x00 0x6b>;
			};
		};

		spdif-0 {

			spdifm0-tx {
				rockchip,pins = <0x00 0x1b 0x01 0x6a>;
				phandle = <0x13>;
			};
		};

		spdif-1 {

			spdifm1-tx {
				rockchip,pins = <0x02 0x11 0x02 0x6a>;
			};
		};

		spdif-2 {

			spdifm2-tx {
				rockchip,pins = <0x00 0x02 0x02 0x6a>;
			};
		};

		sdmmc0-0 {

			sdmmc0m0-pwren {
				rockchip,pins = <0x02 0x07 0x01 0x6d>;
			};

			sdmmc0m0-pin {
				rockchip,pins = <0x02 0x07 0x00 0x6d>;
			};
		};

		sdmmc0-1 {

			sdmmc0m1-pwren {
				rockchip,pins = <0x00 0x1e 0x03 0x6d>;
			};

			sdmmc0m1-pin {
				rockchip,pins = <0x00 0x1e 0x00 0x6d>;
				phandle = <0x76>;
			};
		};

		sdmmc0 {

			sdmmc0-clk {
				rockchip,pins = <0x01 0x06 0x01 0x6e>;
				phandle = <0x54>;
			};

			sdmmc0-cmd {
				rockchip,pins = <0x01 0x04 0x01 0x6f>;
				phandle = <0x55>;
			};

			sdmmc0-dectn {
				rockchip,pins = <0x01 0x05 0x01 0x6d>;
				phandle = <0x56>;
			};

			sdmmc0-wrprt {
				rockchip,pins = <0x01 0x07 0x01 0x6d>;
			};

			sdmmc0-bus1 {
				rockchip,pins = <0x01 0x00 0x01 0x6f>;
			};

			sdmmc0-bus4 {
				rockchip,pins = <0x01 0x00 0x01 0x6f 0x01 0x01 0x01 0x6f 0x01 0x02 0x01 0x6f 0x01 0x03 0x01 0x6f>;
				phandle = <0x57>;
			};

			sdmmc0-pins {
				rockchip,pins = <0x01 0x06 0x00 0x6d 0x01 0x04 0x00 0x6d 0x01 0x05 0x00 0x6d 0x01 0x07 0x00 0x6d 0x01 0x03 0x00 0x6d 0x01 0x02 0x00 0x6d 0x01 0x01 0x00 0x6d 0x01 0x00 0x00 0x6d>;
			};
		};

		sdmmc0ext {

			sdmmc0ext-clk {
				rockchip,pins = <0x03 0x02 0x03 0x70>;
				phandle = <0x63>;
			};

			sdmmc0ext-cmd {
				rockchip,pins = <0x03 0x00 0x03 0x6d>;
				phandle = <0x62>;
			};

			sdmmc0ext-wrprt {
				rockchip,pins = <0x03 0x03 0x03 0x6d>;
			};

			sdmmc0ext-dectn {
				rockchip,pins = <0x03 0x01 0x03 0x6d>;
			};

			sdmmc0ext-bus1 {
				rockchip,pins = <0x03 0x04 0x03 0x6d>;
			};

			sdmmc0ext-bus4 {
				rockchip,pins = <0x03 0x04 0x03 0x6d 0x03 0x05 0x03 0x6d 0x03 0x06 0x03 0x6d 0x03 0x07 0x03 0x6d>;
				phandle = <0x61>;
			};

			sdmmc0ext-pins {
				rockchip,pins = <0x03 0x00 0x00 0x6d 0x03 0x01 0x00 0x6d 0x03 0x02 0x00 0x6d 0x03 0x03 0x00 0x6d 0x03 0x04 0x00 0x6d 0x03 0x05 0x00 0x6d 0x03 0x06 0x00 0x6d 0x03 0x07 0x00 0x6d>;
			};
		};

		sdmmc1 {

			sdmmc1-clk {
				rockchip,pins = <0x01 0x0c 0x01 0x6e>;
				phandle = <0x5c>;
			};

			sdmmc1-cmd {
				rockchip,pins = <0x01 0x0d 0x01 0x6f>;
				phandle = <0x5b>;
			};

			sdmmc1-pwren {
				rockchip,pins = <0x01 0x12 0x01 0x6f>;
			};

			sdmmc1-wrprt {
				rockchip,pins = <0x01 0x14 0x01 0x6f>;
			};

			sdmmc1-dectn {
				rockchip,pins = <0x01 0x13 0x01 0x6f>;
			};

			sdmmc1-bus1 {
				rockchip,pins = <0x01 0x0e 0x01 0x6f>;
			};

			sdmmc1-bus4 {
				rockchip,pins = <0x01 0x0e 0x01 0x6f 0x01 0x0f 0x01 0x6f 0x01 0x10 0x01 0x6f 0x01 0x11 0x01 0x6f>;
				phandle = <0x5a>;
			};

			sdmmc1-pins {
				rockchip,pins = <0x01 0x0c 0x00 0x6d 0x01 0x0d 0x00 0x6d 0x01 0x0e 0x00 0x6d 0x01 0x0f 0x00 0x6d 0x01 0x10 0x00 0x6d 0x01 0x11 0x00 0x6d 0x01 0x12 0x00 0x6d 0x01 0x13 0x00 0x6d 0x01 0x14 0x00 0x6d>;
			};
		};

		emmc {

			emmc-clk {
				rockchip,pins = <0x03 0x15 0x02 0x71>;
				phandle = <0x5e>;
			};

			emmc-cmd {
				rockchip,pins = <0x03 0x13 0x02 0x72>;
				phandle = <0x5f>;
			};

			emmc-pwren {
				rockchip,pins = <0x03 0x16 0x02 0x6a>;
			};

			emmc-rstnout {
				rockchip,pins = <0x03 0x14 0x02 0x6a>;
			};

			emmc-bus1 {
				rockchip,pins = <0x00 0x07 0x02 0x72>;
			};

			emmc-bus4 {
				rockchip,pins = <0x00 0x07 0x02 0x72 0x02 0x1c 0x02 0x72 0x02 0x1d 0x02 0x72 0x02 0x1e 0x02 0x72>;
			};

			emmc-bus8 {
				rockchip,pins = <0x00 0x07 0x02 0x72 0x02 0x1c 0x02 0x72 0x02 0x1d 0x02 0x72 0x02 0x1e 0x02 0x72 0x02 0x1f 0x02 0x72 0x03 0x10 0x02 0x72 0x03 0x11 0x02 0x72 0x03 0x12 0x02 0x72>;
				phandle = <0x60>;
			};
		};

		pwm0 {

			pwm0-pin {
				rockchip,pins = <0x02 0x04 0x01 0x6a>;
				phandle = <0x37>;
			};
		};

		pwm1 {

			pwm1-pin {
				rockchip,pins = <0x02 0x05 0x01 0x6a>;
				phandle = <0x38>;
			};
		};

		pwm2 {

			pwm2-pin {
				rockchip,pins = <0x02 0x06 0x01 0x6a>;
				phandle = <0x39>;
			};
		};

		pwmir {

			pwmir-pin {
				rockchip,pins = <0x02 0x02 0x01 0x6a>;
				phandle = <0x3a>;
			};
		};

		gmac-1 {

			rgmiim1-pins {
				rockchip,pins = <0x01 0x0c 0x02 0x6e 0x01 0x0d 0x02 0x70 0x01 0x13 0x02 0x70 0x01 0x19 0x02 0x6e 0x01 0x15 0x02 0x70 0x01 0x16 0x02 0x70 0x01 0x17 0x02 0x70 0x01 0x0a 0x02 0x70 0x01 0x0b 0x02 0x70 0x01 0x08 0x02 0x6e 0x01 0x09 0x02 0x6e 0x01 0x0e 0x02 0x70 0x01 0x0f 0x02 0x70 0x01 0x10 0x02 0x6e 0x01 0x11 0x02 0x6e 0x00 0x08 0x01 0x6e 0x00 0x0c 0x01 0x6e 0x00 0x18 0x01 0x70 0x00 0x10 0x01 0x6e 0x00 0x11 0x01 0x6e 0x00 0x17 0x01 0x6e 0x00 0x16 0x01 0x6e>;
			};

			rmiim1-pins {
				rockchip,pins = <0x01 0x13 0x02 0x73 0x01 0x19 0x02 0x71 0x01 0x15 0x02 0x73 0x01 0x18 0x02 0x73 0x01 0x16 0x02 0x73 0x01 0x17 0x02 0x73 0x01 0x0a 0x02 0x73 0x01 0x0b 0x02 0x73 0x01 0x08 0x02 0x71 0x01 0x09 0x02 0x71 0x00 0x0b 0x01 0x6a 0x00 0x0c 0x01 0x6a 0x00 0x18 0x01 0x6a 0x00 0x13 0x01 0x6a 0x00 0x10 0x01 0x6a 0x00 0x11 0x01 0x6a>;
			};
		};

		gmac2phy {

			fephyled-speed10 {
				rockchip,pins = <0x00 0x1e 0x01 0x6a>;
			};

			fephyled-duplex {
				rockchip,pins = <0x00 0x1e 0x02 0x6a>;
			};

			fephyled-rxm1 {
				rockchip,pins = <0x02 0x19 0x02 0x6a>;
				phandle = <0x66>;
			};

			fephyled-txm1 {
				rockchip,pins = <0x02 0x19 0x03 0x6a>;
			};

			fephyled-linkm1 {
				rockchip,pins = <0x02 0x18 0x02 0x6a>;
				phandle = <0x67>;
			};
		};

		tsadc_pin {

			tsadc-int {
				rockchip,pins = <0x02 0x0d 0x02 0x6a>;
			};

			tsadc-pin {
				rockchip,pins = <0x02 0x0d 0x00 0x6a>;
			};
		};

		hdmi_pin {

			hdmi-cec {
				rockchip,pins = <0x00 0x03 0x01 0x6a>;
				phandle = <0x4c>;
			};

			hdmi-hpd {
				rockchip,pins = <0x00 0x04 0x01 0x74>;
				phandle = <0x4e>;
			};
		};

		cif-0 {

			dvp-d2d9-m0 {
				rockchip,pins = <0x03 0x04 0x02 0x6a 0x03 0x05 0x02 0x6a 0x03 0x06 0x02 0x6a 0x03 0x07 0x02 0x6a 0x03 0x08 0x02 0x6a 0x03 0x09 0x02 0x6a 0x03 0x0a 0x02 0x6a 0x03 0x0b 0x02 0x6a 0x03 0x01 0x02 0x6a 0x03 0x00 0x02 0x6a 0x03 0x03 0x02 0x6a 0x03 0x02 0x02 0x6a>;
			};
		};

		cif-1 {

			dvp-d2d9-m1 {
				rockchip,pins = <0x03 0x04 0x02 0x6a 0x03 0x05 0x02 0x6a 0x03 0x06 0x02 0x6a 0x03 0x07 0x02 0x6a 0x03 0x08 0x02 0x6a 0x02 0x10 0x04 0x6a 0x02 0x11 0x04 0x6a 0x02 0x12 0x04 0x6a 0x03 0x01 0x02 0x6a 0x03 0x00 0x02 0x6a 0x02 0x0f 0x04 0x6a 0x03 0x02 0x02 0x6a>;
			};
		};

		clk_32k {

			clk-32k-out {
				rockchip,pins = <0x01 0x1c 0x01 0x6a>;
				phandle = <0x5d>;
			};
		};

		pmic {

			pmic-int-l {
				rockchip,pins = <0x02 0x06 0x00 0x6c>;
				phandle = <0x2f>;
			};
		};

		usb2 {

			usb20-host-drv {
				rockchip,pins = <0x00 0x02 0x00 0x6a>;
				phandle = <0x78>;
			};
		};

		leds {

			eth0-link {
				rockchip,pins = <0x02 0x15 0x00 0x6a>;
				phandle = <0x7a>;
			};

			eth0-data {
				rockchip,pins = <0x02 0x16 0x00 0x6a>;
				phandle = <0x79>;
			};
		};

		sdio-pwrseq {

			wifi-enable-h {
				rockchip,pins = <0x01 0x12 0x00 0x70 0x01 0x13 0x00 0x70>;
				phandle = <0x77>;
			};
		};

		bt {

			bt-regon {
				rockchip,pins = <0x01 0x15 0x00 0x74>;
				phandle = <0x26>;
			};

			bt-wake-host {
				rockchip,pins = <0x01 0x1a 0x00 0x6a>;
				phandle = <0x27>;
			};
		};
	};

	chosen {
		stdout-path = "serial2:1500000n8";
	};

	xin32k {
		compatible = "fixed-clock";
		clock-frequency = <0x8000>;
		clock-output-names = "xin32k";
		#clock-cells = <0x00>;
	};

	vcc_sd {
		compatible = "regulator-fixed";
		gpio = <0x75 0x1e 0x01>;
		pinctrl-names = "default";
		pinctrl-0 = <0x76>;
		regulator-name = "vcc_sd";
		regulator-min-microvolt = <0x325aa0>;
		regulator-max-microvolt = <0x325aa0>;
		vin-supply = <0x1e>;
		phandle = <0x58>;
	};

	sdmmcio-regulator {
		compatible = "regulator-gpio";
		gpios = <0x25 0x1c 0x00>;
		states = <0x1b7740 0x01 0x325aa0 0x00>;
		regulator-name = "vccio_sd";
		regulator-type = "voltage";
		regulator-min-microvolt = <0x1b7740>;
		regulator-max-microvolt = <0x325aa0>;
		regulator-always-on;
		vin-supply = <0x1e>;
		startup-delay-us = <0x7d0>;
		regulator-settling-time-us = <0x1388>;
		enable-active-high;
		status = "disabled";
	};

	sdio-pwrseq {
		compatible = "mmc-pwrseq-simple";
		pinctrl-names = "default";
		pinctrl-0 = <0x77>;
		reset-gpios = <0x25 0x12 0x01>;
		phandle = <0x59>;
	};

	vcc-host-5v-regulator {
		compatible = "regulator-fixed";
		gpio = <0x75 0x02 0x01>;
		pinctrl-names = "default";
		pinctrl-0 = <0x78>;
		regulator-name = "vcc_host_5v";
		regulator-always-on;
		regulator-boot-on;
		vin-supply = <0x30>;
	};

	power-management@ff140000 {
		compatible = "rockchip,rk3328-pmu\0syscon\0simple-mfd";
		reg = <0x00 0xff140000 0x00 0x1000>;
	};

	vcc-sys {
		compatible = "regulator-fixed";
		regulator-name = "vcc_sys";
		regulator-always-on;
		regulator-boot-on;
		regulator-min-microvolt = <0x4c4b40>;
		regulator-max-microvolt = <0x4c4b40>;
		phandle = <0x30>;
	};

	vcc-phy-regulator {
		compatible = "regulator-fixed";
		regulator-name = "vcc_phy";
		regulator-always-on;
		regulator-boot-on;
		phandle = <0x65>;
	};

	leds {
		compatible = "gpio-leds";
		pinctrl-names = "default";
		pinctrl-0 = <0x79 0x7a>;

		led-0 {
			gpios = <0x24 0x01 0x01>;
			linux,default-trigger = "mmc0";
		};

		led-1 {
			gpios = <0x24 0x00 0x01>;
			linux,default-trigger = "heartbeat";
		};

		eth0_data_led {
			function = "lan";
			color = <0x01>;
			gpios = <0x2e 0x16 0x00>;
			default-state = "off";
			linux,default-trigger = "stmmac-0:00:100Mbps";
		};

		eth0_link_led {
			function = "lan\0activity";
			color = <0x02>;
			gpios = <0x2e 0x15 0x00>;
			default-state = "off";
			linux,default-trigger = "stmmac-0:00:link";
		};
	};

	spdif-dit {
		compatible = "linux,spdif-dit";
		#sound-dai-cells = <0x00>;
		phandle = <0x11>;
	};

	cpuinfo {
		compatible = "rockchip,cpuinfo";
		nvmem-cells = <0x0a 0x0b>;
		nvmem-cell-names = "id\0cpu-version";
	};

	firmware {

		optee {
			compatible = "linaro,optee-tz";
			method = "smc";
		};
	};
};
